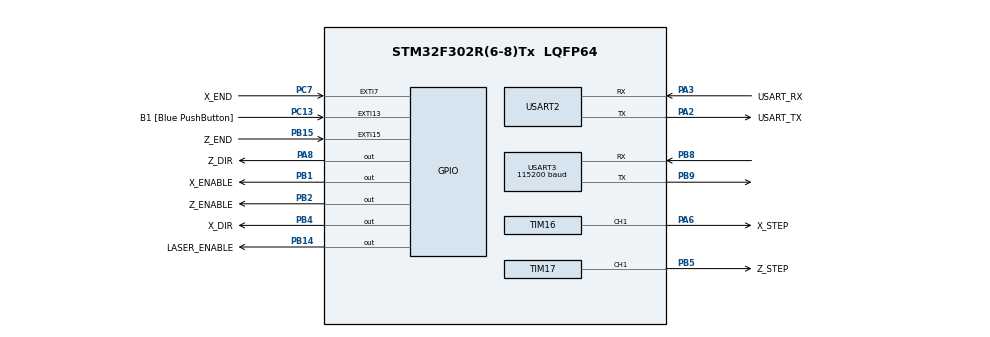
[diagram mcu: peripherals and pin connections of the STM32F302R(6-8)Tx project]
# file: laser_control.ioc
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Dma.Request0=USART3_RX
Dma.USART3_RX.0.Direction=DMA_PERIPH_TO_MEMORY
Dma.USART3_RX.0.Instance=DMA1_Channel3
Dma.USART3_RX.0.MemDataAlignment=DMA_MDATAALIGN_BYTE
Dma.USART3_RX.0.MemInc=DMA_MINC_ENABLE
Dma.USART3_RX.0.Mode=DMA_NORMAL
Dma.USART3_RX.0.PeriphDataAlignment=DMA_PDATAALIGN_BYTE
Dma.USART3_RX.0.PeriphInc=DMA_PINC_DISABLE
Dma.USART3_RX.0.Priority=DMA_PRIORITY_HIGH
Mcu.Family=STM32F3
Mcu.Name=STM32F302R(6-8)Tx
Mcu.Package=LQFP64
NVIC.DMA1_Channel3_IRQn=true\:0\:0\:false\:false\:true\:false\:true\:true
NVIC.EXTI15_10_IRQn=true\:0\:0\:false\:false\:true\:true\:true\:true
NVIC.EXTI9_5_IRQn=true\:0\:0\:false\:false\:true\:true\:true\:true
NVIC.PriorityGroup=NVIC_PRIORITYGROUP_0
NVIC.TIM2_IRQn=true\:0\:0\:false\:false\:true\:true\:true\:true
PA13.GPIO_Label=TMS
PA13.Mode=Serial_Wire
PA13.Signal=SYS_JTMS-SWDIO
PA14.GPIO_Label=TCK
PA14.Mode=Serial_Wire
PA14.Signal=SYS_JTCK-SWCLK
PA2.GPIO_Label=USART_TX
PA2.GPIO_Mode=GPIO_MODE_AF_PP
PA2.GPIO_PuPd=GPIO_NOPULL
PA2.GPIO_Speed=GPIO_SPEED_FREQ_LOW
PA2.Mode=Asynchronous
PA2.Signal=USART2_TX
PA3.GPIO_Label=USART_RX
PA3.GPIO_Mode=GPIO_MODE_AF_PP
PA3.GPIO_PuPd=GPIO_NOPULL
PA3.GPIO_Speed=GPIO_SPEED_FREQ_LOW
PA3.Mode=Asynchronous
PA3.Signal=USART2_RX
PA6.GPIO_Label=X_STEP
PA6.GPIO_PuPd=GPIO_NOPULL
PA6.GPIO_Speed=GPIO_SPEED_FREQ_LOW
PA6.Signal=S_TIM16_CH1
PA8.GPIO_Label=Z_DIR
PA8.GPIO_PuPd=GPIO_PULLDOWN
PA8.PinState=GPIO_PIN_RESET
PA8.Signal=GPIO_Output
PB1.GPIO_Label=X_ENABLE
PB1.GPIO_PuPd=GPIO_NOPULL
PB1.Signal=GPIO_Output
PB14.GPIO_Label=LASER_ENABLE
PB14.GPIO_PuPd=GPIO_PULLDOWN
PB14.Signal=GPIO_Output
PB15.GPIO_Label=Z_END
PB15.GPIO_ModeDefaultEXTI=GPIO_MODE_IT_FALLING
PB15.GPIO_PuPd=GPIO_PULLUP
PB15.Signal=GPXTI15
PB2.GPIO_Label=Z_ENABLE
PB2.GPIO_PuPd=GPIO_NOPULL
PB2.Signal=GPIO_Output
PB4.GPIO_Label=X_DIR
PB4.GPIO_ModeDefaultOutputPP=GPIO_MODE_OUTPUT_PP
PB4.GPIO_PuPd=GPIO_PULLDOWN
PB4.Signal=GPIO_Output
PB5.GPIO_Label=Z_STEP
PB5.GPIO_ModeDefaultPP=GPIO_MODE_AF_PP
PB5.GPIO_PuPd=GPIO_NOPULL
PB5.GPIO_Speed=GPIO_SPEED_FREQ_LOW
PB5.Signal=S_TIM17_CH1
PB8.Mode=Asynchronous
PB8.Signal=USART3_RX
PB9.Mode=Asynchronous
PB9.Signal=USART3_TX
PC13.GPIO_Label=B1 [Blue PushButton]
PC13.GPIO_ModeDefaultEXTI=GPIO_MODE_IT_FALLING
PC13.Signal=GPXTI13
PC14\ -\ OSC32_IN.Mode=LSE-External-Oscillator
PC14\ -\ OSC32_IN.Signal=RCC_OSC32_IN
PC15\ -\ OSC32_OUT.Mode=LSE-External-Oscillator
PC15\ -\ OSC32_OUT.Signal=RCC_OSC32_OUT
PC7.GPIO_Label=X_END
PC7.GPIO_ModeDefaultEXTI=GPIO_MODE_IT_FALLING
PC7.GPIO_PuPd=GPIO_PULLUP
PC7.Signal=GPXTI7
PF0-OSC_IN.Mode=HSE-External-Clock-Source
PF0-OSC_IN.Signal=RCC_OSC_IN
ProjectManager.HeapSize=0x200
ProjectManager.StackSize=0x400
ProjectManager.TargetToolchain=STM32CubeIDE
RCC.AHBFreq_Value=72000000
RCC.APB1CLKDivider=RCC_HCLK_DIV2
RCC.APB1Freq_Value=36000000
RCC.APB1TimFreq_Value=72000000
RCC.APB2Freq_Value=72000000
RCC.APB2TimFreq_Value=72000000
RCC.CortexFreq_Value=72000000
RCC.HCLKFreq_Value=72000000
RCC.HSE_VALUE=8000000
RCC.HSI_VALUE=8000000
RCC.PLLM=8
RCC.PLLMUL=RCC_PLL_MUL9
RCC.PLLN=336
RCC.PLLP=RCC_PLLP_DIV4
RCC.PLLQ=7
RCC.PLLSourceVirtual=RCC_PLLSOURCE_HSE
RCC.PRESCALERUSB=RCC_USBCLKSOURCE_PLL_DIV1_5
RCC.SYSCLKFreq_VALUE=72000000
RCC.SYSCLKSourceVirtual=RCC_SYSCLKSOURCE_PLLCLK
RCC.USBFreq_Value=48000000
SH.S_TIM16_CH1.0=TIM16_CH1,PWM Generation1 CH1
SH.S_TIM17_CH1.0=TIM17_CH1,PWM Generation1 CH1
TIM16.Channel=TIM_CHANNEL_1
TIM16.OC1Preload_PWM=ENABLE
TIM16.OCPolarity_1=TIM_OCPOLARITY_LOW
TIM16.Period=199
TIM16.Pulse=9
TIM17.Channel=TIM_CHANNEL_1
TIM17.OCPolarity_1=TIM_OCPOLARITY_LOW
TIM17.Period=199
TIM17.Pulse=9
TIM2.Period=1999
TIM2.TIM_MasterOutputTrigger=TIM_TRGO_OC1
USART2.VirtualMode-Asynchronous=VM_ASYNC
USART3.BaudRate=115200
USART3.VirtualMode-Asynchronous=VM_ASYNC
VP_TIM16_VS_ClockSourceINT.Mode=Enable_Timer
VP_TIM16_VS_OPM.Mode=OPM_bit
VP_TIM17_VS_ClockSourceINT.Mode=Enable_Timer
VP_TIM17_VS_OPM.Mode=OPM_bit
VP_TIM2_VS_ClockSourceINT.Mode=Internal
board=NUCLEO-F302R8

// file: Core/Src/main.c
/* USER CODE BEGIN Header */
/**
  ******************************************************************************
  * @file           : main.c
  * @brief          : Main program body
  ******************************************************************************
  * @attention
  *
  * Copyright (c) 2022 STMicroelectronics.
  * All rights reserved.
  *
  * This software is licensed under terms that can be found in the LICENSE file
  * in the root directory of this software component.
  * If no LICENSE file comes with this software, it is provided AS-IS.
  *
  ******************************************************************************
  */

/* USER CODE END Header */
#include "main.h"

/* USER CODE BEGIN Includes */
#include "laser.h"
#include "motors.h"
/* USER CODE END Includes */

UART_HandleTypeDef huart2;
UART_HandleTypeDef huart3;
DMA_HandleTypeDef hdma_usart3_rx;

void SystemClock_Config(void);
static void MX_GPIO_Init(void);
static void MX_DMA_Init(void);
static void MX_USART2_UART_Init(void);
static void MX_TIM17_Init(void);
static void MX_TIM16_Init(void);
static void MX_TIM2_Init(void);
static void MX_USART3_UART_Init(void);
/* USER CODE BEGIN PFP */
bool rx_ready = false;

/* USER CODE END PFP */

int main(void)
{

  /* MCU Configuration--------------------------------------------------------*/

  /* Reset of all peripherals, Initializes the Flash interface and the Systick. */
  HAL_Init();

  /* Configure the system clock */
  SystemClock_Config();

  /* Initialize all configured peripherals */
  MX_GPIO_Init();
  MX_DMA_Init();
  MX_USART2_UART_Init();
  MX_TIM17_Init();
  MX_TIM16_Init();
  MX_TIM2_Init();
  MX_USART3_UART_Init();
  /* USER CODE BEGIN 2 */
  my_init();

  /* USER CODE END 2 */

  /* Infinite loop */
  /* USER CODE BEGIN WHILE */
  while (1)
  {
	  my_loop();
    /* USER CODE END WHILE */

    /* USER CODE BEGIN 3 */
	  //HAL_UART_Transmit(&huart3,(uint8_t *) buff, strlen(buff), 200);
	  //LL_mDelay(1000);

  }
  /* USER CODE END 3 */
}

void SystemClock_Config(void)
{
  LL_FLASH_SetLatency(LL_FLASH_LATENCY_2);
  while(LL_FLASH_GetLatency()!= LL_FLASH_LATENCY_2)
  {
  }
  LL_RCC_HSE_EnableBypass();
  LL_RCC_HSE_Enable();

   /* Wait till HSE is ready */
  while(LL_RCC_HSE_IsReady() != 1)
  {

  }
  LL_RCC_PLL_ConfigDomain_SYS(LL_RCC_PLLSOURCE_HSE_DIV_1, LL_RCC_PLL_MUL_9);
  LL_RCC_PLL_Enable();

   /* Wait till PLL is ready */
  while(LL_RCC_PLL_IsReady() != 1)
  {

  }
  LL_RCC_SetAHBPrescaler(LL_RCC_SYSCLK_DIV_1);
  LL_RCC_SetAPB1Prescaler(LL_RCC_APB1_DIV_2);
  LL_RCC_SetAPB2Prescaler(LL_RCC_APB2_DIV_1);
  LL_RCC_SetSysClkSource(LL_RCC_SYS_CLKSOURCE_PLL);

   /* Wait till System clock is ready */
  while(LL_RCC_GetSysClkSource() != LL_RCC_SYS_CLKSOURCE_STATUS_PLL)
  {

  }
  LL_SetSystemCoreClock(72000000);

   /* Update the time base */
  if (HAL_InitTick (TICK_INT_PRIORITY) != HAL_OK)
  {
    Error_Handler();
  }
  LL_RCC_SetTIMClockSource(LL_RCC_TIM17_CLKSOURCE_PCLK2);
  LL_RCC_SetTIMClockSource(LL_RCC_TIM16_CLKSOURCE_PCLK2);
}

static void MX_TIM2_Init(void)
{

  LL_TIM_InitTypeDef TIM_InitStruct = {0};

  /* Peripheral clock enable */
  LL_APB1_GRP1_EnableClock(LL_APB1_GRP1_PERIPH_TIM2);

  /* TIM2 interrupt Init */
  NVIC_SetPriority(TIM2_IRQn, NVIC_EncodePriority(NVIC_GetPriorityGrouping(),0, 0));
  NVIC_EnableIRQ(TIM2_IRQn);

  TIM_InitStruct.Prescaler = 0;
  TIM_InitStruct.CounterMode = LL_TIM_COUNTERMODE_UP;
  TIM_InitStruct.Autoreload = 1999;
  TIM_InitStruct.ClockDivision = LL_TIM_CLOCKDIVISION_DIV1;
  LL_TIM_Init(TIM2, &TIM_InitStruct);
  LL_TIM_DisableARRPreload(TIM2);
  LL_TIM_SetClockSource(TIM2, LL_TIM_CLOCKSOURCE_INTERNAL);
  LL_TIM_SetTriggerOutput(TIM2, LL_TIM_TRGO_CC1IF);
  LL_TIM_DisableMasterSlaveMode(TIM2);

}

static void MX_TIM16_Init(void)
{

  LL_TIM_InitTypeDef TIM_InitStruct = {0};
  LL_TIM_OC_InitTypeDef TIM_OC_InitStruct = {0};
  LL_TIM_BDTR_InitTypeDef TIM_BDTRInitStruct = {0};

  LL_GPIO_InitTypeDef GPIO_InitStruct = {0};

  /* Peripheral clock enable */
  LL_APB2_GRP1_EnableClock(LL_APB2_GRP1_PERIPH_TIM16);

  TIM_InitStruct.Prescaler = 0;
  TIM_InitStruct.CounterMode = LL_TIM_COUNTERMODE_UP;
  TIM_InitStruct.Autoreload = 199;
  TIM_InitStruct.ClockDivision = LL_TIM_CLOCKDIVISION_DIV1;
  TIM_InitStruct.RepetitionCounter = 0;
  LL_TIM_Init(TIM16, &TIM_InitStruct);
  LL_TIM_DisableARRPreload(TIM16);
  LL_TIM_OC_EnablePreload(TIM16, LL_TIM_CHANNEL_CH1);
  TIM_OC_InitStruct.OCMode = LL_TIM_OCMODE_PWM1;
  TIM_OC_InitStruct.OCState = LL_TIM_OCSTATE_DISABLE;
  TIM_OC_InitStruct.OCNState = LL_TIM_OCSTATE_DISABLE;
  TIM_OC_InitStruct.CompareValue = 9;
  TIM_OC_InitStruct.OCPolarity = LL_TIM_OCPOLARITY_LOW;
  TIM_OC_InitStruct.OCNPolarity = LL_TIM_OCPOLARITY_HIGH;
  TIM_OC_InitStruct.OCIdleState = LL_TIM_OCIDLESTATE_LOW;
  TIM_OC_InitStruct.OCNIdleState = LL_TIM_OCIDLESTATE_LOW;
  LL_TIM_OC_Init(TIM16, LL_TIM_CHANNEL_CH1, &TIM_OC_InitStruct);
  LL_TIM_OC_DisableFast(TIM16, LL_TIM_CHANNEL_CH1);
  LL_TIM_SetOnePulseMode(TIM16, LL_TIM_ONEPULSEMODE_SINGLE);
  TIM_BDTRInitStruct.OSSRState = LL_TIM_OSSR_DISABLE;
  TIM_BDTRInitStruct.OSSIState = LL_TIM_OSSI_DISABLE;
  TIM_BDTRInitStruct.LockLevel = LL_TIM_LOCKLEVEL_OFF;
  TIM_BDTRInitStruct.DeadTime = 0;
  TIM_BDTRInitStruct.BreakState = LL_TIM_BREAK_DISABLE;
  TIM_BDTRInitStruct.BreakPolarity = LL_TIM_BREAK_POLARITY_HIGH;
  TIM_BDTRInitStruct.BreakFilter = LL_TIM_BREAK_FILTER_FDIV1;
  TIM_BDTRInitStruct.AutomaticOutput = LL_TIM_AUTOMATICOUTPUT_DISABLE;
  LL_TIM_BDTR_Init(TIM16, &TIM_BDTRInitStruct);
  LL_AHB1_GRP1_EnableClock(LL_AHB1_GRP1_PERIPH_GPIOA);
  /**TIM16 GPIO Configuration
  PA6   ------> TIM16_CH1
  */
  GPIO_InitStruct.Pin = X_STEP_Pin;
  GPIO_InitStruct.Mode = LL_GPIO_MODE_ALTERNATE;
  GPIO_InitStruct.Speed = LL_GPIO_SPEED_FREQ_LOW;
  GPIO_InitStruct.OutputType = LL_GPIO_OUTPUT_PUSHPULL;
  GPIO_InitStruct.Pull = LL_GPIO_PULL_NO;
  GPIO_InitStruct.Alternate = LL_GPIO_AF_1;
  LL_GPIO_Init(X_STEP_GPIO_Port, &GPIO_InitStruct);

}

static void MX_TIM17_Init(void)
{

  LL_TIM_InitTypeDef TIM_InitStruct = {0};
  LL_TIM_OC_InitTypeDef TIM_OC_InitStruct = {0};
  LL_TIM_BDTR_InitTypeDef TIM_BDTRInitStruct = {0};

  LL_GPIO_InitTypeDef GPIO_InitStruct = {0};

  /* Peripheral clock enable */
  LL_APB2_GRP1_EnableClock(LL_APB2_GRP1_PERIPH_TIM17);

  TIM_InitStruct.Prescaler = 0;
  TIM_InitStruct.CounterMode = LL_TIM_COUNTERMODE_UP;
  TIM_InitStruct.Autoreload = 199;
  TIM_InitStruct.ClockDivision = LL_TIM_CLOCKDIVISION_DIV1;
  TIM_InitStruct.RepetitionCounter = 0;
  LL_TIM_Init(TIM17, &TIM_InitStruct);
  LL_TIM_DisableARRPreload(TIM17);
  LL_TIM_OC_EnablePreload(TIM17, LL_TIM_CHANNEL_CH1);
  TIM_OC_InitStruct.OCMode = LL_TIM_OCMODE_PWM1;
  TIM_OC_InitStruct.OCState = LL_TIM_OCSTATE_DISABLE;
  TIM_OC_InitStruct.OCNState = LL_TIM_OCSTATE_DISABLE;
  TIM_OC_InitStruct.CompareValue = 9;
  TIM_OC_InitStruct.OCPolarity = LL_TIM_OCPOLARITY_LOW;
  TIM_OC_InitStruct.OCNPolarity = LL_TIM_OCPOLARITY_HIGH;
  TIM_OC_InitStruct.OCIdleState = LL_TIM_OCIDLESTATE_LOW;
  TIM_OC_InitStruct.OCNIdleState = LL_TIM_OCIDLESTATE_LOW;
  LL_TIM_OC_Init(TIM17, LL_TIM_CHANNEL_CH1, &TIM_OC_InitStruct);
  LL_TIM_OC_DisableFast(TIM17, LL_TIM_CHANNEL_CH1);
  LL_TIM_SetOnePulseMode(TIM17, LL_TIM_ONEPULSEMODE_SINGLE);
  TIM_BDTRInitStruct.OSSRState = LL_TIM_OSSR_DISABLE;
  TIM_BDTRInitStruct.OSSIState = LL_TIM_OSSI_DISABLE;
  TIM_BDTRInitStruct.LockLevel = LL_TIM_LOCKLEVEL_OFF;
  TIM_BDTRInitStruct.DeadTime = 0;
  TIM_BDTRInitStruct.BreakState = LL_TIM_BREAK_DISABLE;
  TIM_BDTRInitStruct.BreakPolarity = LL_TIM_BREAK_POLARITY_HIGH;
  TIM_BDTRInitStruct.BreakFilter = LL_TIM_BREAK_FILTER_FDIV1;
  TIM_BDTRInitStruct.AutomaticOutput = LL_TIM_AUTOMATICOUTPUT_DISABLE;
  LL_TIM_BDTR_Init(TIM17, &TIM_BDTRInitStruct);
  LL_AHB1_GRP1_EnableClock(LL_AHB1_GRP1_PERIPH_GPIOB);
  /**TIM17 GPIO Configuration
  PB5   ------> TIM17_CH1
  */
  GPIO_InitStruct.Pin = Z_STEP_Pin;
  GPIO_InitStruct.Mode = LL_GPIO_MODE_ALTERNATE;
  GPIO_InitStruct.Speed = LL_GPIO_SPEED_FREQ_LOW;
  GPIO_InitStruct.OutputType = LL_GPIO_OUTPUT_PUSHPULL;
  GPIO_InitStruct.Pull = LL_GPIO_PULL_NO;
  GPIO_InitStruct.Alternate = LL_GPIO_AF_10;
  LL_GPIO_Init(Z_STEP_GPIO_Port, &GPIO_InitStruct);

}

static void MX_USART2_UART_Init(void)
{

  huart2.Instance = USART2;
  huart2.Init.BaudRate = 38400;
  huart2.Init.WordLength = UART_WORDLENGTH_8B;
  huart2.Init.StopBits = UART_STOPBITS_1;
  huart2.Init.Parity = UART_PARITY_NONE;
  huart2.Init.Mode = UART_MODE_TX_RX;
  huart2.Init.HwFlowCtl = UART_HWCONTROL_NONE;
  huart2.Init.OverSampling = UART_OVERSAMPLING_16;
  huart2.Init.OneBitSampling = UART_ONE_BIT_SAMPLE_DISABLE;
  huart2.AdvancedInit.AdvFeatureInit = UART_ADVFEATURE_NO_INIT;
  if (HAL_UART_Init(&huart2) != HAL_OK)
  {
    Error_Handler();
  }

}

static void MX_USART3_UART_Init(void)
{

  huart3.Instance = USART3;
  huart3.Init.BaudRate = 115200;
  huart3.Init.WordLength = UART_WORDLENGTH_8B;
  huart3.Init.StopBits = UART_STOPBITS_1;
  huart3.Init.Parity = UART_PARITY_NONE;
  huart3.Init.Mode = UART_MODE_TX_RX;
  huart3.Init.HwFlowCtl = UART_HWCONTROL_NONE;
  huart3.Init.OverSampling = UART_OVERSAMPLING_16;
  huart3.Init.OneBitSampling = UART_ONE_BIT_SAMPLE_DISABLE;
  huart3.AdvancedInit.AdvFeatureInit = UART_ADVFEATURE_NO_INIT;
  if (HAL_UART_Init(&huart3) != HAL_OK)
  {
    Error_Handler();
  }

}

static void MX_DMA_Init(void)
{

  /* DMA controller clock enable */
  __HAL_RCC_DMA1_CLK_ENABLE();

  /* DMA interrupt init */
  /* DMA1_Channel3_IRQn interrupt configuration */
  HAL_NVIC_SetPriority(DMA1_Channel3_IRQn, 0, 0);
  HAL_NVIC_EnableIRQ(DMA1_Channel3_IRQn);

}

static void MX_GPIO_Init(void)
{
  LL_EXTI_InitTypeDef EXTI_InitStruct = {0};
  LL_GPIO_InitTypeDef GPIO_InitStruct = {0};

  /* GPIO Ports Clock Enable */
  LL_AHB1_GRP1_EnableClock(LL_AHB1_GRP1_PERIPH_GPIOC);
  LL_AHB1_GRP1_EnableClock(LL_AHB1_GRP1_PERIPH_GPIOF);
  LL_AHB1_GRP1_EnableClock(LL_AHB1_GRP1_PERIPH_GPIOA);
  LL_AHB1_GRP1_EnableClock(LL_AHB1_GRP1_PERIPH_GPIOB);

  /**/
  LL_GPIO_ResetOutputPin(GPIOB, X_ENABLE_Pin|Z_ENABLE_Pin|LASER_ENABLE_Pin|X_DIR_Pin);

  /**/
  LL_GPIO_ResetOutputPin(Z_DIR_GPIO_Port, Z_DIR_Pin);

  /**/
  LL_SYSCFG_SetEXTISource(LL_SYSCFG_EXTI_PORTC, LL_SYSCFG_EXTI_LINE13);

  /**/
  LL_SYSCFG_SetEXTISource(LL_SYSCFG_EXTI_PORTB, LL_SYSCFG_EXTI_LINE15);

  /**/
  LL_SYSCFG_SetEXTISource(LL_SYSCFG_EXTI_PORTC, LL_SYSCFG_EXTI_LINE7);

  /**/
  LL_GPIO_SetPinPull(B1_GPIO_Port, B1_Pin, LL_GPIO_PULL_NO);

  /**/
  LL_GPIO_SetPinPull(Z_END_GPIO_Port, Z_END_Pin, LL_GPIO_PULL_UP);

  /**/
  LL_GPIO_SetPinPull(X_END_GPIO_Port, X_END_Pin, LL_GPIO_PULL_UP);

  /**/
  LL_GPIO_SetPinMode(B1_GPIO_Port, B1_Pin, LL_GPIO_MODE_INPUT);

  /**/
  LL_GPIO_SetPinMode(Z_END_GPIO_Port, Z_END_Pin, LL_GPIO_MODE_INPUT);

  /**/
  LL_GPIO_SetPinMode(X_END_GPIO_Port, X_END_Pin, LL_GPIO_MODE_INPUT);

  /**/
  EXTI_InitStruct.Line_0_31 = LL_EXTI_LINE_13;
  EXTI_InitStruct.Line_32_63 = LL_EXTI_LINE_NONE;
  EXTI_InitStruct.LineCommand = ENABLE;
  EXTI_InitStruct.Mode = LL_EXTI_MODE_IT;
  EXTI_InitStruct.Trigger = LL_EXTI_TRIGGER_FALLING;
  LL_EXTI_Init(&EXTI_InitStruct);

  /**/
  EXTI_InitStruct.Line_0_31 = LL_EXTI_LINE_15;
  EXTI_InitStruct.Line_32_63 = LL_EXTI_LINE_NONE;
  EXTI_InitStruct.LineCommand = ENABLE;
  EXTI_InitStruct.Mode = LL_EXTI_MODE_IT;
  EXTI_InitStruct.Trigger = LL_EXTI_TRIGGER_FALLING;
  LL_EXTI_Init(&EXTI_InitStruct);

  /**/
  EXTI_InitStruct.Line_0_31 = LL_EXTI_LINE_7;
  EXTI_InitStruct.Line_32_63 = LL_EXTI_LINE_NONE;
  EXTI_InitStruct.LineCommand = ENABLE;
  EXTI_InitStruct.Mode = LL_EXTI_MODE_IT;
  EXTI_InitStruct.Trigger = LL_EXTI_TRIGGER_FALLING;
  LL_EXTI_Init(&EXTI_InitStruct);

  /**/
  GPIO_InitStruct.Pin = X_ENABLE_Pin|Z_ENABLE_Pin;
  GPIO_InitStruct.Mode = LL_GPIO_MODE_OUTPUT;
  GPIO_InitStruct.Speed = LL_GPIO_SPEED_FREQ_LOW;
  GPIO_InitStruct.OutputType = LL_GPIO_OUTPUT_PUSHPULL;
  GPIO_InitStruct.Pull = LL_GPIO_PULL_NO;
  LL_GPIO_Init(GPIOB, &GPIO_InitStruct);

  /**/
  GPIO_InitStruct.Pin = LASER_ENABLE_Pin|X_DIR_Pin;
  GPIO_InitStruct.Mode = LL_GPIO_MODE_OUTPUT;
  GPIO_InitStruct.Speed = LL_GPIO_SPEED_FREQ_LOW;
  GPIO_InitStruct.OutputType = LL_GPIO_OUTPUT_PUSHPULL;
  GPIO_InitStruct.Pull = LL_GPIO_PULL_DOWN;
  LL_GPIO_Init(GPIOB, &GPIO_InitStruct);

  /**/
  GPIO_InitStruct.Pin = Z_DIR_Pin;
  GPIO_InitStruct.Mode = LL_GPIO_MODE_OUTPUT;
  GPIO_InitStruct.Speed = LL_GPIO_SPEED_FREQ_LOW;
  GPIO_InitStruct.OutputType = LL_GPIO_OUTPUT_PUSHPULL;
  GPIO_InitStruct.Pull = LL_GPIO_PULL_DOWN;
  LL_GPIO_Init(Z_DIR_GPIO_Port, &GPIO_InitStruct);

  /* EXTI interrupt init*/
  NVIC_SetPriority(EXTI9_5_IRQn, NVIC_EncodePriority(NVIC_GetPriorityGrouping(),0, 0));
  NVIC_EnableIRQ(EXTI9_5_IRQn);
  NVIC_SetPriority(EXTI15_10_IRQn, NVIC_EncodePriority(NVIC_GetPriorityGrouping(),0, 0));
  NVIC_EnableIRQ(EXTI15_10_IRQn);

}

void Error_Handler(void)
{
  __disable_irq();
  while (1)
  {
  }
}
